# psc3m6 register map
Vendor: Infineon Technologies; Series: PSC3M6; File version: 1.0
CPU: CM33 r0p1, little endian, MPU, FPU, DSP, VTOR, 3 interrupt priority bits, 167 interrupts
Registers are 32-bit, read-write, reset 0x0 unless marked. A register's access mark holds for its fields unless they carry their own. Offsets are from the block's base; [hi:lo] are bit positions; lines under a group give offsets from that group; {n}, {i} and the like mark numbered series; <NAME> marks a mode.

## FLASHC
Base 0x42150000
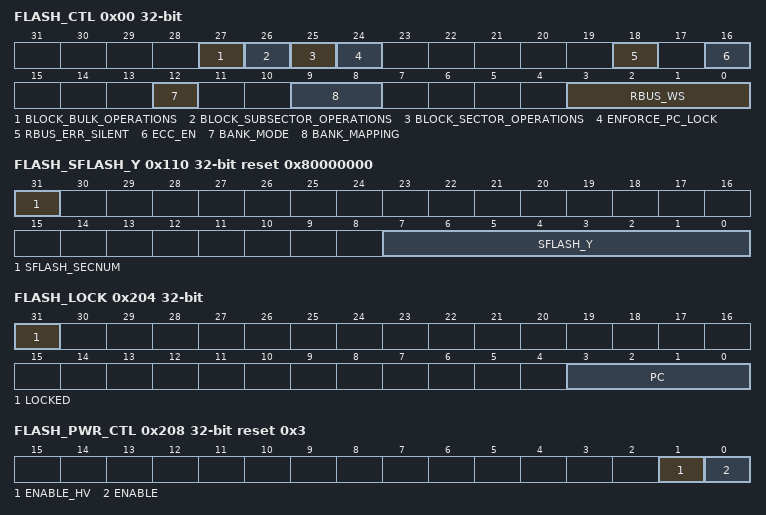
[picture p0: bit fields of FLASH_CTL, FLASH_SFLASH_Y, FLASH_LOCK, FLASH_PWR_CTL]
0x00 FLASH_CTL — Flash control
  [27] BLOCK_BULK_OPERATIONS write-1-sets — This bit can be set once and not cleared thereafter. When set it is no longer possible to perform bulk erase or bulk DFT operations. The flash controller will block any write operations to the FM_CTL register pertaining to such operations.
  [26] BLOCK_SUBSECTOR_OPERATIONS write-1-sets — This bit can be set once and not cleared thereafter. When set it is no longer possible to perform subsector erase or subsector DFT operations. The flash controller will block any write operations to the FM_CTL register pertaining to such operations.
  [25] BLOCK_SECTOR_OPERATIONS write-1-sets — This bit can be set once and not cleared thereafter. When set it is no longer possible to perform sector erase or sector DFT operations. The flash controller will block any write operations to the FM_CTL register pertaining to such operations.
  [24] ENFORCE_PC_LOCK write-1-sets — This bit can be set once and not cleared thereafter. When set the PC inheritiance and locking mechanism described with the FLASH_LOCK register is enabled. When cleared, access to the flash controller and flash macro is possible from any protection context with appropriate PPC permissions.
  [18] RBUS_ERR_SILENT — Please note that it is SW's responsibility that I$ of M33 must be disabled before setting RBUS_ERR_SILENT HIGH. Otherwise, the erroneous goes to I$ which is NOT desired. Specifies bus transfer behavior for a non-recoverable error on the FLASH macro main interface (either a non-correctable ECC error, a FLASH macro main interface internal error, a FLASH macro main interface memory hole access): 0: Bus transfer has a bus error. 1: Bus transfer does NOT have a bus error; i.e. the error is 'silent' In either case, the erroneous FLASH macro data is returned to CPU since I$ is disabled. This field is ONLY used by CPU bus transfers. Non-CPU bus transfers always have a bus transfer with a bus error and fault/interrupt, in case of a non-recoverable error. Note: All CPU bus masters have dedicated status registers (CM33 to register the occurrence of FLASH macro main interface (R-bus) internal errors. Note: fault reporting can be used to identify the error that occurred: - FLASH macro main interface internal error. - FLASH macro main interface non-recoverable ECC error. - FLASH macro main interface recoverable ECC error (over its threshold). - FLASH macro main interface memory hole error.
  [16] ECC_EN — Enable ECC checking for FLASH main (R-bus) interface: 0: Disabled. ECC checking/reporting on FLASH main interface is disabled. No correctable or non-correctable faults are reported. 1: Enabled.
  [12] BANK_MODE — Specifies bank mode of FLASH macro main array. 0: Single bank mode. 1: Dual bank mode.
  [9:8] BANK_MAPPING — Specifies mapping of FLASH macro main subregion. 00: MAIN (Mapping A), WORK (Mapping A). 01: MAIN (Mapping B), WORK (Mapping A). 10: MAIN (Mapping A), WORK (Mapping B). 11: MAIN (Mapping B), WORK (Mapping B). This field is only used when MAIN_BANK_MODE is '1' (dual bank mode).
  [3:0] RBUS_WS — FLASH macro main interface (R-bus) wait states: '0': 0 wait states. ... '15': 15 wait states
0x104 FLASH_SECTOR_M ro — # of sector of a FM
  [31:0] SECTOR_M — # of sectors of a FM, must be an even number, same value as RTL parameter SECTOR_M.
0x108 FLASH_MAIN_N ro — Size of MAIN in 8KB block for each pair of sectors
  [31:0] MAIN_N — Size of MAIN_NVM in 8KB blocks for each pair of sectors, same value as RTL parameter MAIN_N.
0x10C FLASH_WORK_Z ro — Size of WORK in 8KB block for each pair of sectors
  [31:0] WORK_Z — Size of WORK_NVM in 8KB blocks for each pair of sectors, same value as RTL parameter WORK_Z, the value WORK_Z can be zero.
0x110 FLASH_SFLASH_Y ro reset 0x80000000 — Size of SLFASH in 8KB block in Sector 1
  [31] SFLASH_SECNUM — 0: Not allowed 1: SM only in Sector 1
  [7:0] SFLASH_Y — Size of SFLASH_NVM in 8KB blocks in Sector 1, same value as RTL parameter SFLASH_Y.
0x114 FLASH_REFRESH_ROW ro — Size of refresh rows for each sector
  [31:0] REFRESH_ROW — Size of refresh rows for each sector, same value as RTL parameter REFRESH_ROW All sectors of a FM must have the same refresh rows It is 4 per sector for s40flash.3 FM.
0x200 FLASH_CMD — Command
  [1] BUFF_INV write-1-sets — Invalidation of ALL buffers. SW writes a '1' to clear the buffers. HW sets this field to '0' when the operation is completed. The operation takes a maximum of three clock cycles.
0x204 FLASH_LOCK — Flash Controller Lock Register
  [31] LOCKED — Software writes this register bit to 1 to 'lock' the flash controller to its own protection context (after setting the protection context by writing to a flash memory location). Once set, any subsequent (AHB) writes result in bus error and operation ignored. Software (FLASH.PC) reads back this field to check whether the lock succeeded. Software (FLASH_LOCK.PC) clears this field when it has completed a program/erase operation. To avoid deadlock and for management purpose, HW entitles PC0 the omnipotent capability to read FLASH_LOCK.PC and to release FLASH_LOCK.LOCKED no matter which PC acquires it. All PCs allowed by PPC can access FLASH_LOCK when its LOCKED bit is LOW (not locked).
  [3:0] PC ro — When FLASH_LOCK is acquired, even PPC allows, further MMIO access is possible only to this FLASH_LOCK.PC (& same HMASTER_ID) irrespective of corresponding PPC attributes. Other PCs or the same PC but different HMASTER_ID violation results in bus error & operation ignored. There is no further interrupt/fault triggered for this violation.
0x208 FLASH_PWR_CTL reset 0x3 — Flash power control
  [1] ENABLE_HV — Controls 'enable_hv' pin of the Flash memory.
  [0] ENABLE — Controls 'enable' pin of the Flash memory.
0x20C ENFORCE_PC_LOCK_SHADOW ro — Shadow bit of FLASH_CTL.ENFORCE_PC_LOCK
  [0] PC_LOCK_SHADOW — Shadow register of FLASH_CTL.ENFORCE_PC_LOCK. Read only irrespective of PPC's configuration.
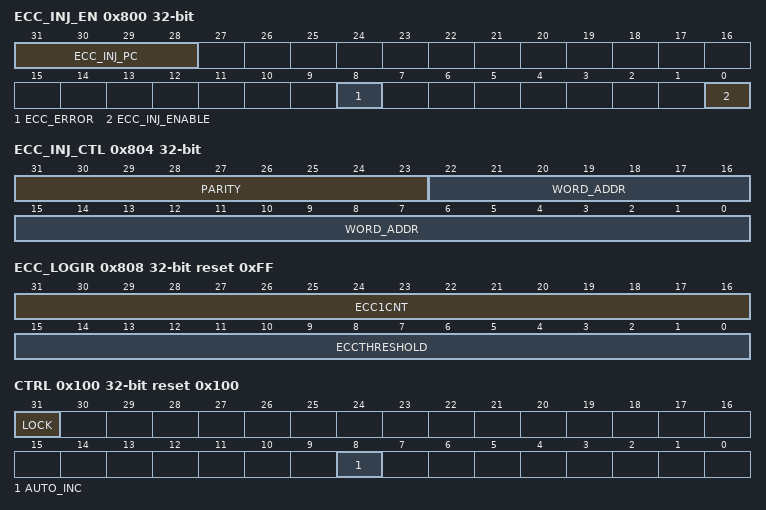
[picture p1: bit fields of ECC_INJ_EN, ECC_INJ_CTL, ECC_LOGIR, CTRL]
0x800 ECC_INJ_EN — ECC injection enable on read
  [31:28] ECC_INJ_PC ro — The PC is inherited from the master who enabled ECC_INJ_ENABLE (while ECC_INJ_ENABLE is low)
  [8] ECC_ERROR — 1'b0: If the injected ECC does not trigger any non-recoverable error (ECC errors <= 1). 1'b1: If the injected ECC triggers non-recoverable error (ECC errors >= 2). The AHB read transaction results in bus error. There is no additional fault/interrupt trigged. SW writes to this register are ignored if SW writes value other than the real RTL value (there is HW write when value written from SW does not match with the RTL value for this). The mxs40flashc HW clears ECC_INJ_EN.ECC_ERROR when SW clears ECC_INJ_EN.ECC_ERROR or ECC_INJ_EN.ECC_INJ_ENABLE (write value of '0').
  [0] ECC_INJ_ENABLE — Enable ECC error injection for FLASH R-bus interface (while FLASH_CTL.ECC_EN enabled) . 1'b0: ECC_INJ_EN is disabled. 1'b1: ECC_INJ_EN is enabled. Only the PC specified by ECC_INJ_PC can access (read/write) ECC_INJ_ENABLE and ECC_ERROR when ECC_INJ_ENABLE is high excpet PC0 which can access it at any time to break the potential deadlock of ECC_INJ_EN.
0x804 ECC_INJ_CTL — ECC injection control
  [31:23] PARITY — ECC parity to use for ECC error injection at address WORD_ADDR. The 9-bit ECC PARITY[8:0] is for a 128bit long word.
  [22:0] WORD_ADDR — Specifies the word address where an error will be injected. The word address WORD_ADDR[22:0] is FM column address (module-internal offset), including cxa, bax, axa, sector, row/page definitions. On a FLASH R-bus read and when ECC_INJ_EN bit is '1', and when ECC_INJ_EN.ECC_INJ_PC value matches, the parity (PARITY[8:0]) replaces the FM parity. When ECC_INJ_ENABLE is 1'b1, only PC specified by ECC_INJ_EN.ECC_INJ_PC can access (read/write) WORD_ADDR and PARITY.
0x808 ECC_LOGIR reset 0xFF — Interrupt threshold for number of ECC correctable error
  [31:16] ECC1CNT — Number of ECC single-bit failures detected and corrected during the memory read operations. Write value of 16'b0 is allowed to clear ECC_LOGIR.ECC1CNT (when the number of ECC single-bit failures detected and corrected reaches threshold value). It is recommended that SW should not write any value other than 0 to register ECC_LOGIR.ECC1CNT
  [15:0] ECCTHRESHOLD — Interrupt/fault threshold for number of ECC single-bit failures detected and corrected indicated in bit[31:16]. The # of failures must be one larger than ECCTHRESHOLD to trigger interrupt/fault.' For example, while ECCTHRESHOLD is 0xFF, only upon the 256th failures, the ECC Fault information will be reported on flashc_main_c_ecc_mmio_fault_* output pins (fault will be triggered). After the 256th failures, ECC_LOGIR.ECC1CNT will stay saturated at 0xFF and will not overrun. ECCTHRESHOLD of zero is not supported.
0x1000 MPC group — MPC Memory Protection Controller registers
  0x00 CFG — Config register with error response, RegionID PPC_MPC_MAIN is the security owner PC. The error response configuration is located in CFG.RESPONSE, only one such configuration exists applying to all protection contexts in the system.
    [4] RESPONSE — Response Configuration for Security and PC violations 0: Read-Zero Write Ignore (RAZ/WI) 1: Bus Error
  0x100 CTRL reset 0x100 — Control register with lock bit and auto-increment only (Separate CTRL for each PC depends on access_pc)
    [31] LOCK write-1-sets — Security lockdown for this protection context. Software can set this bit but not clear it once set. When set, write operations to BLK_LUT are not possible from this protection context. Setting LOCK also blocks writes to CTRL itself (for that PC copy). All writes are ignored.
    [8] AUTO_INC — Auto-increment BLK_IDX by 1 for this protection context as a side effect of each read/write access to BLK_LUT
  0x104 BLK_MAX ro — Max value of block-based index register
    [31:0] VALUE — Maximum value of block-based index register. The number and size blocks in an MPC is design time configurable and for embedded memories defaults to covering the entire memory using 4kB blocks; See product datasheet for details on protection of external memories.
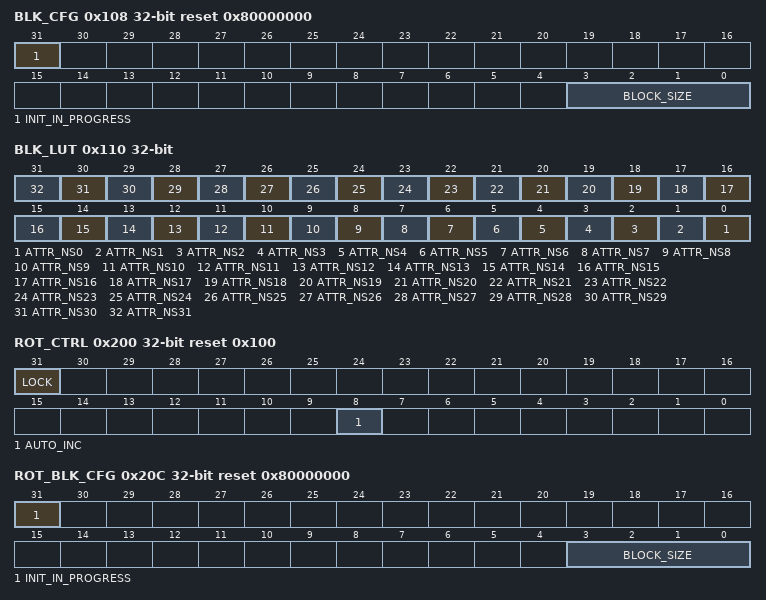
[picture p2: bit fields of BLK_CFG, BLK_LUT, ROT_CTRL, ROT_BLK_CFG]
  0x108 BLK_CFG ro reset 0x80000000 — Block size & initialization in progress
    [31] INIT_IN_PROGRESS — During initialization INIT_IN_PROGRESS is '1' and MMIO register accesses to BLK_LUT is blocked (BLK_IDX increment is also ignored). The block attributes are retained in DeepSleep (and obviously Active) power mode. Initialization is only required from a power mode in which the block attributes are not retained. E.g., initialization is required for a cold boot (after a Power-on-Reset). HW initializes the block attributes: the NS attributes are set to '0' (secure), the R attributes are set to '1' (read access allowed) and the W attributes are set to '1' (write access allowed). During initialization, the MPC supports memory accesses (memory accesses are NOT blocked) with the initialization block attribute values as mentioned above. This e.g. allows MPC initialization to proceed in parallel with boot program memory accesses (as opposed to serializing the two), improving device boot time.
    [3:0] BLOCK_SIZE — Block size of individually protected blocks (0: 32B, 1: 64B, ... up to 15: 1MB) Block size= (1<<(BLOCK_SIZE+5)) The number and size blocks in an MPC is design time configurable and for embedded memories defaults to covering the entire memory using 4kB blocks; see product datasheet for details on protection of external memories.
  0x10C BLK_IDX — Index of 32-block group accessed through BLK_LUT (Separate IDX for each PC depending on access_pc)
    [31:0] VALUE — Index value for accessing block-based lookup table using BLK_LUT. Programming out of LUT range is an user error and it loops back to '0' once overflow occurs.
  0x110 BLK_LUT — NS status for 32 blocks at BLK_IDX with PC=<access_pc>
    [n] ATTR_NS{n} (n=0..31) — NS bit for block {n} based on BLK_IDX
  0x200 ROT_CTRL reset 0x100 — Control register with lock bit and auto-increment only
    [31] LOCK write-1-sets — Security lockdown for the root-of-trust configuration registers. Software can set this bit but not clear it once set. When set, write operations to ROT_BLK_LUT are not possible. Write is ignored.
    [8] AUTO_INC — Auto-increment ROT_BLK_IDX by 1 for each read/write of ROT_BLK_LUT
  0x208 ROT_BLK_MAX ro — Max value of block-based index register for ROT
    [31:0] VALUE — Maximum value of block-based index register. The number and size blocks in an MPC is design time configurable and for embedded memories defaults to covering the entire memory using 4kB blocks; see product datasheet for details on protection of external memories.
  0x20C ROT_BLK_CFG ro reset 0x80000000 — Same as BLK_CFG
    [31] INIT_IN_PROGRESS — During initialization INIT_IN_PROGRESS is '1' and MMIO register accesses to ROT_BLK_LUT is RAZWI. The block attributes are retained in DeepSleep (and obviously Active) power mode. Initialization is only required from a power mode in which the block attributes are not retained. E.g., initialization is required for a cold boot (after a Power-on-Reset). HW initializes the block attributes: the NS attributes are set to '0' (secure), the R attributes are set to '1' (read access allowed) and the W attributes are set to '1' (write access allowed). During initialization, the MPC supports memory accesses (memory accesses are NOT blocked) with the initialization block attribute values as mentioned above. This e.g. allows MPC initialization to proceed in parallel with boot program memory accesses (as opposed to serializing the two), improving device boot time.
    [3:0] BLOCK_SIZE — Block size of individually protected blocks (0: 32B, 1: 64B, ...up to 15:1MB) Block size= (1<<(BLOCK_SIZE+5)) The number and size blocks in an MPC is design time configurable and for embedded memories defaults to covering the entire memory using 4kB blocks; see product datasheet for details on protection of external memories.
  0x210 ROT_BLK_IDX — Index of 8-block group accessed through ROT_BLK_LUT_*
    [31:0] VALUE — Index value for accessing block-based lookup table using ROT_BLK_LUT. Programming out of LUT range is an user error and it loops back to '0' once overflow occurs.
  0x214 ROT_BLK_PC — Protection context of 8-block group accesses through ROT_BLK_LUT
    [3:0] PC — Specify PC values for ROT_BLK_IDX and ROT_BLK_LUT
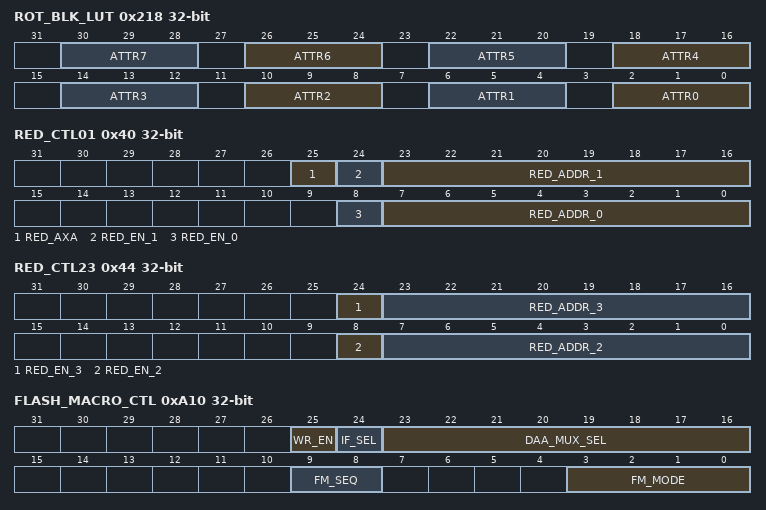
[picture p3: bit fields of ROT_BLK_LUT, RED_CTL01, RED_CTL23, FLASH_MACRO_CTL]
  0x218 ROT_BLK_LUT — (R,W,NS) bits for 8 blocks at ROT_BLK_IDX for PC=ROT_BKL_PC
    [4n+2:4n] ATTR{n} (n=0..7) — W/R/NS bits for block {n} indicated by ROT_BLK_IDX for ROT_BLK_PC PC
0x2000 FM_CTL group — Flash Macro Registers are maintained by SONOS FM team. Please read 002-26677 BROS for details.
  0x40 RED_CTL01 — Redundancy Control normal sectors 0,1
    [25] RED_AXA — '1': Redundancy Enable for SM Rows in Sector 1; Uses RED_ADDR_1 bits for Bad Row Pair Address
    [24] RED_EN_1 — '1': Redundancy Enable for Sector 1
    [23:16] RED_ADDR_1 — Bad Row Pair Address for Sector 1
    [8] RED_EN_0 — '1': Redundancy Enable for Sector 0
    [7:0] RED_ADDR_0 — Bad Row Pair Address for Sector 0
  0x44 RED_CTL23 — Redundancy Control normal sectors 2,3
    [24] RED_EN_3 — 1': Redundancy Enable for Sector 3
    [23:16] RED_ADDR_3 — Bad Row Pair Address for Sector 3
    [8] RED_EN_2 — 1': Redundancy Enable for Sector 2
    [7:0] RED_ADDR_2 — Bad Row Pair Address for Sector 2
  {0x800+4j} FM_PL_DATA[{j}] (j=0..131) — Flash macro Page Latches data
    [31:0] DATA32 — Normal PL data read: four page latch Bytes When reading the page latches it requires FM_CTL.IF_SEL to be '1' Note: the high Voltage page latches are readable for test mode functionality.
  0xA10 FLASH_MACRO_CTL — Flash macro control
    [25] WR_EN — 0: normal mode 1: Fm Write Enable Note: IF_SEL and WR_EN cannot be changed at the same time
    [24] IF_SEL — Interface selection. Specifies the interface that is used for flash memory read operations: 0: R interface is used (default value). In this case, the flash memory address is provided as part of the R signal interface. 1: C interface is used. In this case, the flash memory address is provided by FM_MEM_ADDR (the page address) and by the C interface access offset in the FM_MEM_DATA structure. Note: IF_SEL and WR_EN cannot be changed at the same time
    [23:16] DAA_MUX_SEL — Direct memory cell access address.
    [9:8] FM_SEQ — Requires (IF_SEL|WR_EN)=1 Flash macro sequence selection
    [3:0] FM_MODE — Requires (IF_SEL|WR_EN)=1 Flash macro mode selection
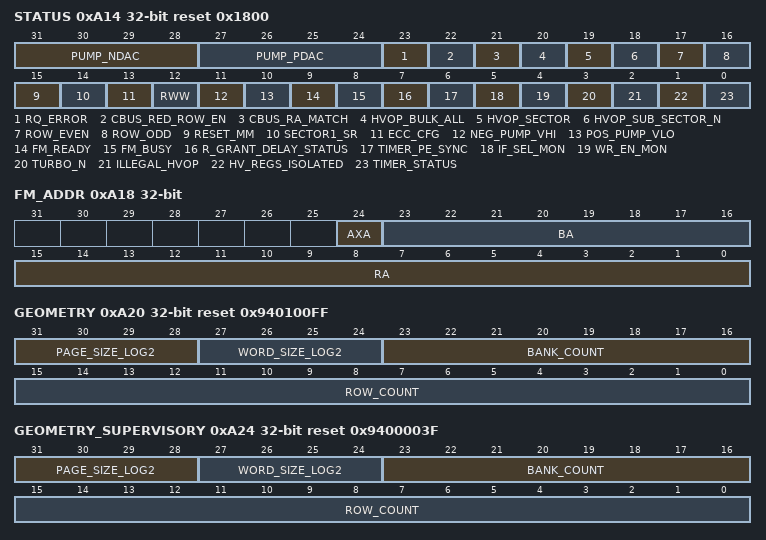
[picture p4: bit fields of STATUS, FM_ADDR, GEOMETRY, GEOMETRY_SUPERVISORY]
  0xA14 STATUS ro reset 0x1800
    [31:28] PUMP_NDAC — Test_only, internal node: regif ndac outputs to pos pump
    [27:24] PUMP_PDAC — Test_only, internal node: regif pdac outputs to pos pump
    [23] RQ_ERROR — Test_only, internal node: rq_error sync-de in clk_c domain
    [22] CBUS_RED_ROW_EN — Test_only, internal node: mpcon red_row_en
    [21] CBUS_RA_MATCH — Test_only, internal node: mpcon ra match
    [20] HVOP_BULK_ALL — Test_only, internal node: mpcon bk_all
    [19] HVOP_SECTOR — Test_only, internal node: mpcon bk_sec
    [18] HVOP_SUB_SECTOR_N — Test_only, internal node: mpcon bk_subb
    [17] ROW_EVEN — Test_only, internal node: mpcon row_even
    [16] ROW_ODD — Test_only, internal node: mpcon row_odd
    [15] RESET_MM — Test_only, internal node: mpcon reset_mm
    [14] SECTOR1_SR — 0: Sector 1 does not contain special rows. The special rows are located in separate special sectors. 1: Sector 1 contains special rows
    [13] ECC_CFG — Geometry ECC configuration: 0: FM with No ECC 1: FM with ECC
    [12] RWW — FM Type (Read While Write or Not Read While Write): 0: Non RWW FM Type 1: RWW FM Type
    [11] NEG_PUMP_VHI
    [10] POS_PUMP_VLO
    [9] FM_READY — 0: FM not ready 1: FM ready
    [8] FM_BUSY — 0': FM not busy 1: FM BUSY : R_GRANT is 0 as result of a busy request from FM ready, or from HV operations.
    [7] R_GRANT_DELAY_STATUS — 0: R_GRANT_DELAY timer is not running 1: R_GRANT_DELAY timer is running
    [6] TIMER_PE_SYNC — The actual timer state sync-ed in clk_c domain: 0: timer is not running: 1: timer is running;
    [5] IF_SEL_MON — FM_CTL.IF_SEL bit after being synchronized in clk_r domain
    [4] WR_EN_MON — FM_CTL.WR_EN bit after being synchronized in clk_r domain
    [3] TURBO_N — After FM power up indicates the analog blocks currents are boosted to faster reach their functional state.. Used in the testchip boot only as an 'FM READY' flag. 0: turbo mode 1: normal mode
    [2] ILLEGAL_HVOP — Indicates a bulk,sector erase, program has been requested when axa=1 0: no error 1: illegal HV operation error
    [1] HV_REGS_ISOLATED — Indicates the isolation status at HV trim and redundancy registers inputs 0: Not isolated, writing permitted 1: isolated writing disabled
    [0] TIMER_STATUS — This is the timer_en bit set by writing a '1' in the TIMER_CTL bit 31. It is reset by HW when the timer expires 0: timer not running 1: Timer is enabled and not expired yet
  0xA18 FM_ADDR — Flash macro address
    [24] AXA — Auxiliairy address field: 0: regular flash memory. 1: supervisory flash memory.
    [23:16] BA — Bank address.
    [15:0] RA — Row address.
  0xA1C BOOKMARK — Bookmark register - keeps the current FW HV seq
    [31:0] BOOKMARK — Used by FW. Keeps the Current HV cycle sequence
  0xA20 GEOMETRY ro reset 0x940100FF — Regular flash geometry
    [31:28] PAGE_SIZE_LOG2 — Number of Bytes per page (log 2): 0: 1 Byte 1: 2 Bytes 2: 4 Bytes ... 15: 32768 Bytes The currently planned flash macros have a page size of either 256 Byte or 512 Byte, resulting in PAGE_SIZE_LOG2 settings of 8 and 9 respectively. All 4 macros used in the PSC3M6 family will see this field as 9
    [27:24] WORD_SIZE_LOG2 — Number of Bytes per word (log 2). A word is defined as the data that is read from the flash macro over the R interface with a single read access: 0: 1 Byte 1: 2 Bytes 2: 4 Bytes ... 3: 128 Bytes The currently planned flash macros have a word size of either 32-bit, 64-bit or 128-bit, resulting in WORD_SIZE_LOG2 settings of 2, 3 and 4 respectively. All 4 macros used in the PSC3M6 family will see this field as 4
    [23:16] BANK_COUNT — Number of banks (minus 1): 0: 1 bank 1: 2 banks ... '255': 256 banks For 128kB, 256kB and 512kB macros the value of this field is 1 (2 banks) For 1MB macro the value of this field is 3 (4 banks)
    [15:0] ROW_COUNT — Number of rows (minus 1): 0: 1 row 1: 2 rows 2: 3 rows ... '65535': 65536 rows For 128kB macro the value of this field is x7F (128 rows) For 256kB macro the value of this field is xFF (256 rows) For 512kB macro the value of this field is x1FF (512 rows) For 1MB macro the value of this field is x1FF (512 rows)
  0xA24 GEOMETRY_SUPERVISORY ro reset 0x9400003F — Supervisory flash geometry
    [31:28] PAGE_SIZE_LOG2 — Number of Bytes per page (log 2). See GEOMETRY.PAGE_SIZE_LOG2. Typically, PAGE_SIZE_LOG2 equals GEOMETRY.PAGE_SIZE_LOG2.
    [27:24] WORD_SIZE_LOG2 — Number of Bytes per word (log 2). See GEOMETRY.WORD_SIZE_LOG2. Typically, WORD_SIZE_LOG2 equals GEOMETRY.WORD_SIZE_LOG2.
    [23:16] BANK_COUNT — Number of banks (minus 1). BANK_COUNT is less or equal to GEOMETRY.BANK_COUNT.
    [15:0] ROW_COUNT — Number of rows (minus 1). ROW_COUNT is typically less than GEOMETRY.ROW_COUNT
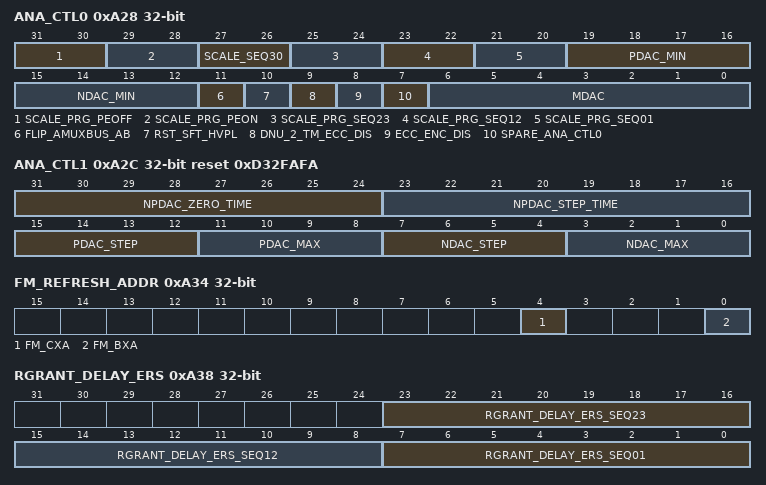
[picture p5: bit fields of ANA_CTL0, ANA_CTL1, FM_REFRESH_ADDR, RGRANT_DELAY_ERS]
  0xA28 ANA_CTL0 — Analog control 0
    [31:30] SCALE_PRG_PEOFF — PROG&PRE_PROG: Scale for R_GRANT_DELAY on PE OFF transition: 00: 0.125uS 01: 1uS 10: 10uS 11: 100uS
    [29:28] SCALE_PRG_PEON — PROG&PRE_PROG: Scale for R_GRANT_DELAY on PE On transition: 00: 0.125uS 01: 1uS 10: 10uS 11: 100uS
    [27:26] SCALE_SEQ30 — PROG&PRE_PROG& ERASE: Scale for R_GRANT_DELAY on seq3-seq0 transition: 00: 0.125uS 01: 1uS 10: 10uS 11: 100uS
    [25:24] SCALE_PRG_SEQ23 — PROG&PRE_PROG: Scale for R_GRANT_DELAY on seq2-seq3 transition: 00: 0.125uS 01: 1uS 10: 10uS 11: 100uS
    [23:22] SCALE_PRG_SEQ12 — PROG&PRE_PROG: Scale for R_GRANT_DELAY on seq1-seq2 transition: 00: 0.125uS 01: 1uS 10: 10uS 11: 100uS
    [21:20] SCALE_PRG_SEQ01 — PROG&PRE_PROG: Scale for R_GRANT_DELAY on seq0-seq1 transition: 00: 0.125uS 01: 1uS 10: 10uS 11: 100uS
    [19:16] PDAC_MIN — PDAC staircase min value
    [15:12] NDAC_MIN — NDAC staircase min value
    [11] FLIP_AMUXBUS_AB — Flips amuxbusa and amuxbusb 0: amuxbusa, amuxbusb 1: amuxbusb, amuxbusb
    [10] RST_SFT_HVPL — 1: Page Latches Soft Reset
    [9] DNU_2_TM_ECC_DIS ro — Do Not Use this bit as it is for test Mode use only. Write only to 0 in normal mode (tm_ecc_dis in RTL)
    [8] ECC_ENC_DIS — 0': ECC encoder is enabled for the FM with ECC feature. The PL ECC bits are loaded automatically '1': ECC encoder disabled. - The Macro needs to be in C-BUS mode - IF_SEL=1 to write and keep this bit at 1
    [7] SPARE_ANA_CTL0 — Spare bit
    [6:0] MDAC — Trimming of the output margin Voltage as a function of Vpos and Vneg.
  0xA2C ANA_CTL1 reset 0xD32FAFA — Analog control 1
    [31:24] NPDAC_ZERO_TIME — Ndac/Pdac LO duration: (1uS .. 255uS) * 8 When 0, N/PDAC don't return to 0
    [23:16] NPDAC_STEP_TIME — Ndac/Pdac step duration: (1uS .. 255uS) * 8 When = 0 N/PDAC_MAX control the pumps
    [15:12] PDAC_STEP — Pdac step increment
    [11:8] PDAC_MAX — Pdac Max Value.Trimming of positive pump output Voltage:
    [7:4] NDAC_STEP — Ndac step increment
    [3:0] NDAC_MAX — Ndac Max Value.Trimming of negative pump output Voltage.
  0xA30 FM_PL_WRDATA_ALL — Flash macro write page latches all
    [31:0] DATA32 — Write all high Voltage page latches with the same 32-bit data in a single write cycle. In order to also write same lower 8bit from 32-bit data to all the ECC bits in the page latches, set ANA_CTL0.ECC_ENC_DIS=1. Read always returns 0. Used for test mode and sims only
  0xA34 FM_REFRESH_ADDR — Address bit to point to scratch area
    [4] FM_CXA — Address bit to point to Column 33 0: Point to normal columns in sector 1: Point to Column 33 used for BL Disturb Counter. For engineering use only.
    [0] FM_BXA — Address bit to point to scratch area 0: Point to normal rows in sector 1: Point to scratch rows in sector. For engineering use only.
  0xA38 RGRANT_DELAY_ERS — R-grant delay for erase
    [23:16] RGRANT_DELAY_ERS_SEQ23 — ERASE: R-grant blocking delay on seq2-seq3 transition. Scale = ANA_CTL0.SCALE_SEQ23 When = 0 R_GRANT_DELAY control is disabled when IF_SEL=1 R_GRANT_DELAY control is disabled
    [15:8] RGRANT_DELAY_ERS_SEQ12 — ERASE: R-grant blocking delay on seq1-seq2 transition. Scale = ANA_CTL0.SCALE_SEQ12 When = 0 R_GRANT_DELAY control is disabled when IF_SEL=1 R_GRANT_DELAY control is disabled
    [7:0] RGRANT_DELAY_ERS_SEQ01 — ERASE: R-grant blocking delay on seq0-seq1 transition. Scale = ANA_CTL0.SCALE_SEQ01 When = 0 R_GRANT_DELAY control is disabled when IF_SEL=1 R_GRANT_DELAY control is disabled
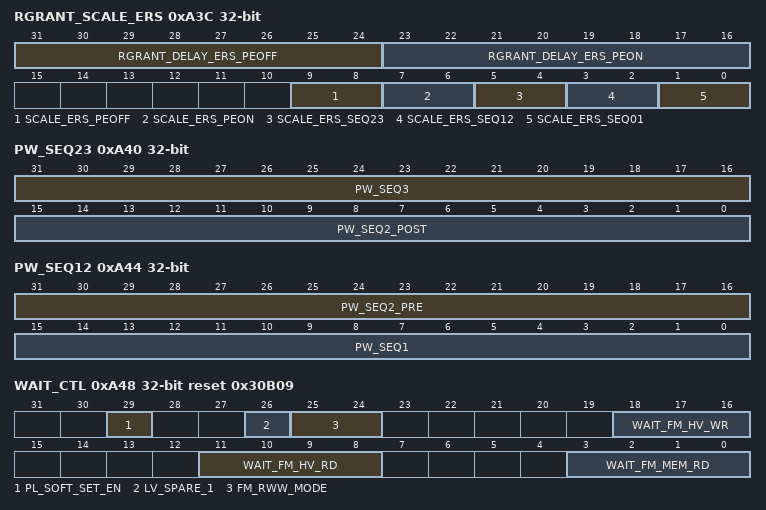
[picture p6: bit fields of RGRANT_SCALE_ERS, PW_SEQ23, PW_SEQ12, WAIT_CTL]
  0xA3C RGRANT_SCALE_ERS — R-grant delay scale for erase
    [31:24] RGRANT_DELAY_ERS_PEOFF — ERASE: R-grant blocking delay on PE OFF. Scale = ANA_CTL0.SCALE_PEOFF When = 0 R_GRANT_DELAY control is disabled when IF_SEL=1 R_GRANT_DELAY control is disabled
    [23:16] RGRANT_DELAY_ERS_PEON — ERASE: R-grant blocking delay on PE ON. Scale = ANA_CTL0.SCALE_PEON When = 0 R_GRANT_DELAY control is disabled when IF_SEL=1 R_GRANT_DELAY control is disabled
    [9:8] SCALE_ERS_PEOFF — ERASE: Scale for R_GRANT_DELAY on PE OFF transition: '00': 0.125uS '01': 1uS '10': 10uS '11': 100uS
    [7:6] SCALE_ERS_PEON — ERASE: Scale for R_GRANT_DELAY on PE On transition: '00': 0.125uS '01': 1uS '10': 10uS '11': 100uS
    [5:4] SCALE_ERS_SEQ23 — ERASE: Scale for R_GRANT_DELAY on seq2-seq3 transition: '00': 0.125uS '01': 1uS '10': 10uS '11': 100uS
    [3:2] SCALE_ERS_SEQ12 — ERASE: Scale for R_GRANT_DELAY on seq1-seq2 transition: '00': 0.125uS '01': 1uS '10': 10uS '11': 100uS
    [1:0] SCALE_ERS_SEQ01 — ERASE: Scale for R_GRANT_DELAY on seq0-seq1 transition: '00': 0.125uS '01': 1uS '10': 10uS '11': 100uS
  0xA40 PW_SEQ23 — HV Pulse Delay for seq2 post & seq3
    [31:16] PW_SEQ3 — Seq3 delay
    [15:0] PW_SEQ2_POST — Seq2 post delay
  0xA44 PW_SEQ12 — HV Pulse Delay for seq 1&2 pre
    [31:16] PW_SEQ2_PRE — Seq2 pre delay
    [15:0] PW_SEQ1 — Seq1 delay
  0xA48 WAIT_CTL reset 0x30B09 — Wait State control
    [29] PL_SOFT_SET_EN — Page latch soft set enable, 0 = disabled, 1 = enabled (at end of seq_2), taken care in API
    [26] LV_SPARE_1 — Spare register
    [25:24] FM_RWW_MODE — 2'b00: Full CBUS MODE 2'b01: RWW 2'b10: RWW. R_GRANT is stalling r_bus for the whole program/erase duration
    [18:16] WAIT_FM_HV_WR — Number of C interface wait cycles (on 'clk_c') for a write to the Page Latches.
    [11:8] WAIT_FM_HV_RD — Number of C interface wait cycles (on 'clk_c') for a read from the Page Latches. Common for reading HV Page Latches and the DATA_COMP_RESULT bit
    [3:0] WAIT_FM_MEM_RD — Number of C interface wait cycles (on 'clk_c') for a read from the memory
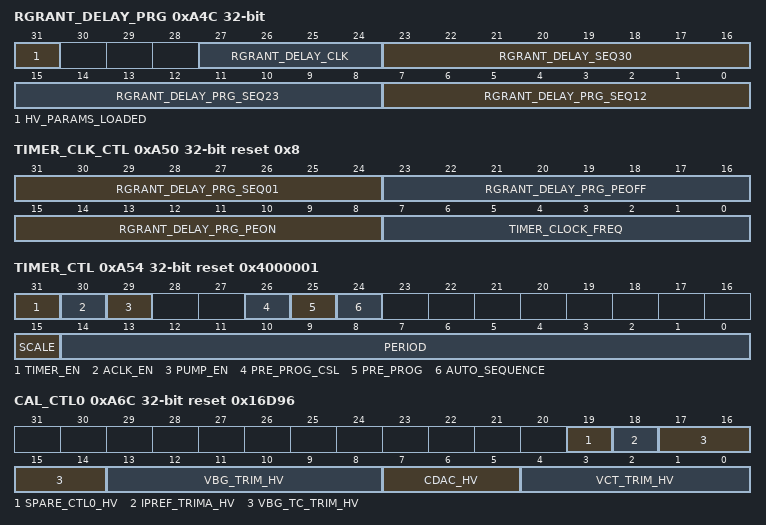
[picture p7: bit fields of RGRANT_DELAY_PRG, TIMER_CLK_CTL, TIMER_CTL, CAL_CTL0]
  0xA4C RGRANT_DELAY_PRG — R-grant delay for program
    [31] HV_PARAMS_LOADED — 0': HV Pulse common params not loaded '1': HV Pulse common params loaded: r-grant delays, r-grant scale, prescaler, timer values for seq1,seq2_pre, seq2_post, seq3
    [27:24] RGRANT_DELAY_CLK — Frequency divider from clk_t to create the 8MHz reference clock for R_grant delay. The value of 0 is equivalent with 1. If the clock clk_t = 8MHz the value needs to be 1 The value of this field is the integer result of 'clk_t frequency / 8'. Example: for clk_t=100 this field is INT(100/8) =12. This field is updated at runtime with the 'SW_RGRANT_DELAY_CLK ' value from the HV parameters table
    [23:16] RGRANT_DELAY_SEQ30 — PROG&PRE_PROG & ERASE: R-grant blocking delay on seq3-seq0 transition. Scale = ANA_CTL0.SCALE_SEQ30 When = 0 R_GRANT_DELAY control is disabled when IF_SEL=1 R_GRANT_DELAY control is disabled
    [15:8] RGRANT_DELAY_PRG_SEQ23 — PROG&PRE_PROG: R-grant blocking delay on seq2-seq3 transition. Scale = ANA_CTL0.SCALE_SEQ23 When = 0 R_GRANT_DELAY control is disabled when IF_SEL=1 R_GRANT_DELAY control is disabled
    [7:0] RGRANT_DELAY_PRG_SEQ12 — PROG&PRE_PROG: R-grant blocking delay on seq1-seq2 transition. Scale = ANA_CTL0.SCALE_SEQ12 When = 0 R_GRANT_DELAY control is disabled when IF_SEL=1 R_GRANT_DELAY control is disabled
  0xA50 TIMER_CLK_CTL reset 0x8 — Timer prescaler (clk_t to timer clock frequency divider)
    [31:24] RGRANT_DELAY_PRG_SEQ01 — PROG&PRE_PROG: R-grant blocking delay on seq0-seq1 transition. Scale = ANA_CTL0.SCALE_SEQ01 When = 0 R_GRANT_DELAY control is disabled when IF_SEL=1 R_GRANT_DELAY control is disabled
    [23:16] RGRANT_DELAY_PRG_PEOFF — PROG&PRE_PROG: R-grant blocking delay on PE OFF. Scale = ANA_CTL0.SCALE_PEOFF When = 0 R_GRANT_DELAY control is disabled when IF_SEL=1 R_GRANT_DELAY control is disabled
    [15:8] RGRANT_DELAY_PRG_PEON — PROG&PRE_PROG: R-grant blocking delay on PE ON. Scale = ANA_CTL0.SCALE_PEON When = 0 R_GRANT_DELAY control is disabled when IF_SEL=1 R_GRANT_DELAY control is disabled
    [7:0] TIMER_CLOCK_FREQ — Clk_t frequency divider to provide the 1MHz reference clock for the Regif Timer. Equal to the frequency in MHz of the timer clock 'clk_t'. Example: if 'clk_t' has a frequency of 4 MHz then this field value is '4' Max clk_t frequency = 100MHz. This field is updated at runtime with the 'SW_TIMER_CLOCK_FREQ ' value from the HV parameters table
  0xA54 TIMER_CTL reset 0x4000001 — Timer control
    [31] TIMER_EN — Timer enable: 0: disabled 1: enabled. SW sets this field to '1' to start the timer. HW sets this field to '0' when the timer is expired.
    [30] ACLK_EN — ACLK enable (generates a single cycle pulse for the FM): 0: disabled 1: enabled. SW set this field to '1' to generate a single cycle pulse. HW sets this field to '0' when the pulse is generated.
    [29] PUMP_EN — Pump enable: 0: disabled 1: enabled (also requires FM_CTL.IF_SEL to be'1', this additional restriction is required to prevent non intentional clearing of the FM). SW sets this field to '1' to generate a single PE pulse. HW clears this field when timer is expired.
    [26] PRE_PROG_CSL — 0: CSL lines driven by MDAC 1: CSL lines driven by VNEG_G
    [25] PRE_PROG — 1 during pre-program operation
    [24] AUTO_SEQUENCE — 1': Starts1 the HV automatic sequencing Cleared by HW
    [15] SCALE — Timer tick scale: 0: 1 microsecond. 1: 100 microseconds.
    [14:0] PERIOD — Timer period in either microseconds (SCALE is '0') or 100's of microseconds (SCALE is '1') multiples.
  0xA58 ACLK_CTL wo — MPCON clock
    [0] ACLK_GEN — Write '1b1' to generate one clock pulse for HV control registers (mpcon outputs)
  0xA5C INTR — Interrupt
    [0] TIMER_EXPIRED write-1-clears — Set to '1', when event is detected. Write INTR field with '1', to clear bit. Write INTR_SET field with '1', to set bit.
  0xA60 INTR_SET — Interrupt set
    [0] TIMER_EXPIRED write-1-sets — Write INTR_SET field with '1' to set corresponding INTR field (a write of '0' has no effect).
  0xA64 INTR_MASK — Interrupt mask
    [0] TIMER_EXPIRED — Mask for corresponding field in INTR register.
  0xA68 INTR_MASKED ro — Interrupt masked
    [0] TIMER_EXPIRED — Logical and of corresponding request and mask fields.
  0xA6C CAL_CTL0 reset 0x16D96 — Cal control - VCT, VBG, CDAC, IPREF
    [19] SPARE_CTL0_HV — Spare trim bits, DNU
    [18] IPREF_TRIMA_HV — Adds 100-150nA boost on IPREF
    [17:14] VBG_TC_TRIM_HV — Bandgap Voltage Temperature Compensation trim control
    [13:8] VBG_TRIM_HV — Bandgap Voltage trim control.
    [7:5] CDAC_HV — Temperature compensated trim DAC. To control Vctat slope for VNEG.
    [4:0] VCT_TRIM_HV — Bandgap Voltage Temperature Compensation trim control.
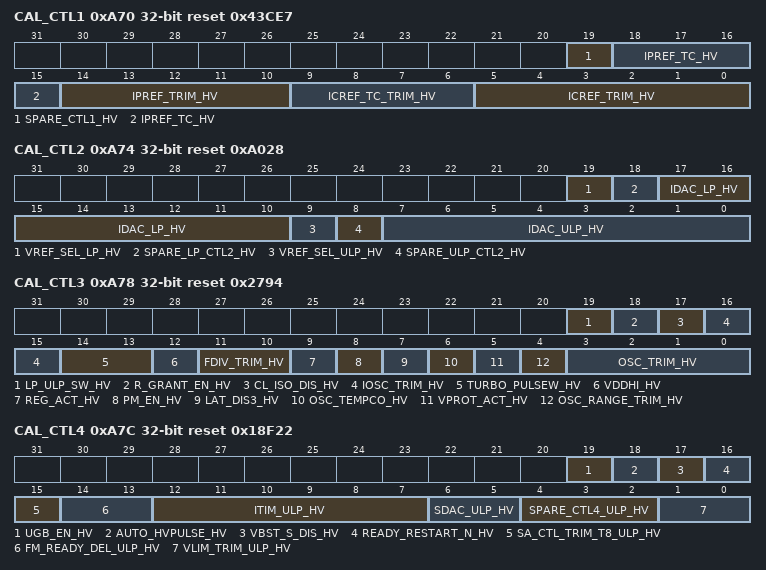
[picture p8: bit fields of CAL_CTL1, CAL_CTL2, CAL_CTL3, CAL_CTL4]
  0xA70 CAL_CTL1 reset 0x43CE7 — Cal control - ICREF, IPREF
    [19] SPARE_CTL1_HV — Spare trim bit, DNU
    [18:15] IPREF_TC_HV — IPREF Slope Control
    [14:10] IPREF_TRIM_HV — Bandgap IPTAT trim control.
    [9:6] ICREF_TC_TRIM_HV — Bandgap Current Temperature Compensation trim control
    [5:0] ICREF_TRIM_HV — Bandgap Current trim control.
  0xA74 CAL_CTL2 reset 0xA028 — Cal control - IDAC, IBS_CTL, LAT_DIS
    [19] VREF_SEL_LP_HV — 0: Uses VBG as reference for VLIM - LP Mode 1: Uses VCTAT as reference for VLIM - LP mode
    [18] SPARE_LP_CTL2_HV — Spare bit to be used in LP configuration
    [17:10] IDAC_LP_HV — Sets the sense current reference offset value. Refer to trim tables for details.
    [9] VREF_SEL_ULP_HV — 0: Uses VBG as reference for VLIM - ULP Mode 1: Uses VCTAT as reference for VLIM - ULP mode
    [8] SPARE_ULP_CTL2_HV — Spare bit to be used in ULP configuration
    [7:0] IDAC_ULP_HV — Sets the sense current reference offset value. Refer to trim tables for details.
  0xA78 CAL_CTL3 reset 0x2794 — Cal control - OSC trims, FDIV, REG_ACT, TURBO, LP_ULP_SW
    [19] LP_ULP_SW_HV — LP<-->ULP switch for trim signals: 0: LP 1: ULP
    [18] R_GRANT_EN_HV — 0: r_grant handshake disabled, r_grant always 1. 1: r_grant handshake enabled
    [17] CL_ISO_DIS_HV — 0: The internal logic controlls the CL isolation 1: Forces CL bypass
    [16:15] IOSC_TRIM_HV — Oscillator Bias Current Trim during Standby 0.33 uA -- 1.65 uA
    [14:13] TURBO_PULSEW_HV — Turbo pulse width trim (Typical) 00: 40 us 01: 20 us 10: 15 us 11: 8 us
    [12] VDDHI_HV — 0: vdd < 2.3V 1: vdd >= 2.3V '0' setting can used for vdd > 2.3V also, but with a current penalty.
    [11:10] FDIV_TRIM_HV — FDIV_TRIM_HV[1:0]: Assuming oscillator frequency of 8MHz in standby. Following are the clock frequencies seen by doubler 00: F = 0.5MHz 01: F = 1MHz 10: F = 2MHz 11: F = 4MHz
    [9] REG_ACT_HV — 0: VBST regulator will operate in active/standby mode based on control signal. 1: Forces the VBST regulator in active mode all the time
    [8] PM_EN_HV — 0: Sense Amp bias similar to _ver2 1: pbias enabled in Sense Amp for Better Margin
    [7] LAT_DIS3_HV — 0: Enable saen3 control for data out latches 1: Disable saen3 control for data out latches
    [6] OSC_TEMPCO_HV — 0: Uses VBG as reference 1: Uses VCTAT as reference
    [5] VPROT_ACT_HV — Forces VPROT in active mode all the time
    [4] OSC_RANGE_TRIM_HV — 0: Oscillator Low Frequency range 1: Oscillator High Frequency Range
    [3:0] OSC_TRIM_HV — Flash macro pump clock trim control.
  0xA7C CAL_CTL4 reset 0x18F22 — Cal control - VLIM, IDAC, SDAC, ITIM ULP trims
    [19] UGB_EN_HV — UGB enable in TM control
    [18] AUTO_HVPULSE_HV — 0: HV Pulse controlled by FW 1: HV Pulse controlled by Hardware
    [17] VBST_S_DIS_HV — 0: VBST_S voltage for each sector to allow VBST level to be dropped to VCC during Erase in the selected sector, reducing coupling to GBL. 1: VBST_S voltage for each sector stays at VBST level during Erase in the selected sector.
    [16] READY_RESTART_N_HV — Toggle: 1-->0, ready goes low, ready will remain low as long as the bit is low. Toggle the bit back to 1 to activate the ready logic. To be used by API only.
    [15] SA_CTL_TRIM_T8_ULP_HV — saen3 pulse width trim (Current trim)
    [14:13] FM_READY_DEL_ULP_HV — 00: Default : delay 1ns 01: Delayed by 1.5us 10: Delayed by 2.0us 11: Delayed by 2.5us
    [12:7] ITIM_ULP_HV — Trimming of timing current
    [6:5] SDAC_ULP_HV — Sets the sense current reference temp slope. Refer to trim tables for details.
    [4:2] SPARE_CTL4_ULP_HV
    [1:0] VLIM_TRIM_ULP_HV — VLIM_TRIM[1:0]: 00: V2 = 650mV 01: V2 = 700mV 10: V2 = 750mV - Default 11: V2 = 800mV
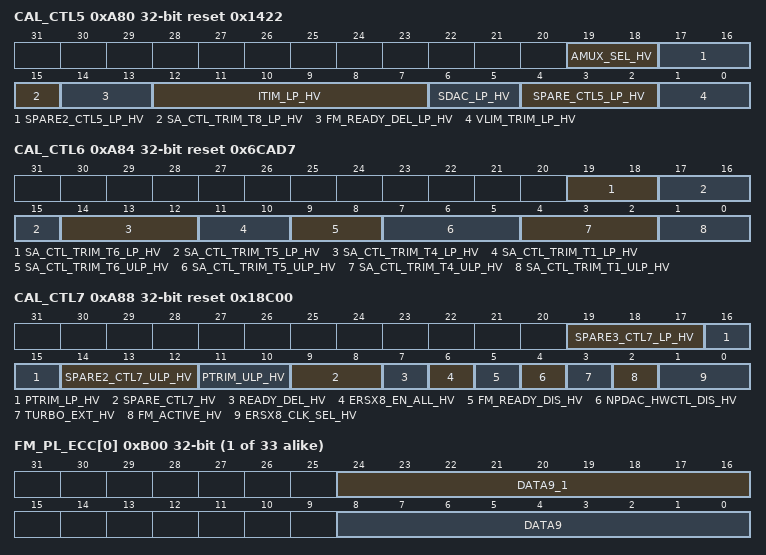
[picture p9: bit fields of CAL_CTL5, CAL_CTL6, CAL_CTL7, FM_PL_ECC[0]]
  0xA80 CAL_CTL5 reset 0x1422 — Cal control - VLIM, IDAC, SDAC, ITIM LP trims
    [19:18] AMUX_SEL_HV — Amux Select in AMUX_UGB 00: Bypass UGB for both amuxbusa and amuxbusb 01: Bypass UGB for amuxbusb while passing amuxbusa through UGB. 10: Bypass UGB for amuxbusa while passing amuxbusb through UGB. 11: UGB Calibrate mode
    [17:16] SPARE2_CTL5_LP_HV — Spare Bit, not used
    [15] SA_CTL_TRIM_T8_LP_HV — saen3 pulse width trim (Current trim)
    [14:13] FM_READY_DEL_LP_HV — 00: Delayed by 1us 01: Delayed by 1.5us 10: Delayed by 2.0us 11: Delayed by 2.5us
    [12:7] ITIM_LP_HV — Trimming of timing current
    [6:5] SDAC_LP_HV — Sets the sense current reference temp slope. Refer to trim tables for details.
    [4:2] SPARE_CTL5_LP_HV — Spare Bit, not used
    [1:0] VLIM_TRIM_LP_HV — VLIM_TRIM[1:0]: 00: V2 = 650mV 01: V2 = 700mV 10: V2 = 750mV - Default 11: V2 = 800mV
  0xA84 CAL_CTL6 reset 0x6CAD7 — Cal control - SA CTL LP/ULP trims
    [19:18] SA_CTL_TRIM_T6_LP_HV — SA_CTL_TRIM_T6_LP_HV<1>= eni (enable current trim) SA_CTL_TRIM_T6_LP_HV<0> = ecn (enable cap trim)
    [17:15] SA_CTL_TRIM_T5_LP_HV — SA_CTL_TRIM_T5_LP_HV<2>= evi (integration current trim) SA_CTL_TRIM_T5_LP_HV<1:0> = evc (integration cap trim)
    [14:12] SA_CTL_TRIM_T4_LP_HV — SA_CTL_TRIM_T4_LP_HV<2>= eqi (eq current trim) SA_CTL_TRIM_T4_LP_HV<1:0> = eqc (eq cap trim)
    [11:10] SA_CTL_TRIM_T1_LP_HV — clk_trk delay
    [9:8] SA_CTL_TRIM_T6_ULP_HV — SA_CTL_TRIM_T6_ULP_HV<1>= eni (enable current trim) SA_CTL_TRIM_T6_ULP_HV<0> = ecn (enable cap trim)
    [7:5] SA_CTL_TRIM_T5_ULP_HV — SA_CTL_TRIM_T5_ULP_HV<2>= evi (integration current trim) SA_CTL_TRIM_T5_ULP_HV<1:0> = evc (integration cap trim)
    [4:2] SA_CTL_TRIM_T4_ULP_HV — SA_CTL_TRIM_T4_ULP_HV<2>= eqi (eq current trim) SA_CTL_TRIM_T4_ULP_HV<1:0> = eqc (eq cap trim)
    [1:0] SA_CTL_TRIM_T1_ULP_HV — clk_trk delay
  0xA88 CAL_CTL7 reset 0x18C00 — Cal control - ERSX8_CLK_SEL, FM_ACTIVE, TURBO_EXT
    [19:17] SPARE3_CTL7_LP_HV
    [16:15] PTRIM_LP_HV — SA PBIAS Trim for LP Operation
    [14:12] SPARE2_CTL7_ULP_HV
    [11:10] PTRIM_ULP_HV — SA PBIAS Trim for ULP Operation
    [9:8] SPARE_CTL7_HV
    [7] READY_DEL_HV — 0: Ready Delay trim. 1: Ready Delay trim.
    [6] ERSX8_EN_ALL_HV — 0': Staggered turn on/off of GWL 1: GWL are turned on/off at the same time (old FM legacy)
    [5] FM_READY_DIS_HV — 0': fm ready is enabled 1: fm ready is disabled (fm_ready is always '1')
    [4] NPDAC_HWCTL_DIS_HV — 0': ndac, pdac staircase hardware controlled 1: ndac, pdac staircase disabled. Enables FW control.
    [3] TURBO_EXT_HV — 0: Normal operation 1: Uses external turbo pulse
    [2] FM_ACTIVE_HV — 0: Normal operation 1: Forces FM SYS in active mode
    [1:0] ERSX8_CLK_SEL_HV — Clock frequency into the ersx8 shift register block 00: Oscillator clock 01: Oscillator clock / 2 10: Oscillator clock / 4 11: Oscillator clock / 8
  {0xB00+4j} FM_PL_ECC[{j}] (j=0..32) — Flash macro Page Latches ECC
    [24:16] DATA9_1 ro — ECC encoder output. Can be read any time at address 0xa00
    [8:0] DATA9 — if_sel must be 1 Normal PL ECC data read: one page latch Byte When reading the page latches it requires FM_CTL.IF_SEL to be '1' Note: the high Voltage page latches are readable for test mode functionality. Only even addresses, address step =8.
  {0xC00+4j} FM_MEM_DATA[{j}] (j=0..131) ro — Flash macro memory sense amplifier data
    [31:0] DATA32 — Sense amplifier and column multiplexer structure Bytes. The read data is dependent on FM_CTL.IF_SEL - IF_SEL is 0: data as specified by the R interface address; If accessed when IF_SEL=0, the data read is not valid. - IF_SEL is 1: data as specified by FM_MEM_ADDR and the offset of the accessed FM_MEM_DATA register. Four FM data out Bytes. Each access is a full FM core read through C-BUS. The row address is given by the FM_ADDRESS register, the word and column addresses are driven by c_addr bus.
  {0xF00+4j} FM_MEM_ECC[{j}] (j=0..32) ro — Flash macro memory sense amplifier ECC.
    [8:0] ECC_PARITY — Sense amplifier ECC Bits. FM_CTL.IF_SEL must be 1. FM ECC data. Each access is a full FM core read through C-BUS. The row address is given by the FM_ADDRESS register, the word and column addresses are driven by c_addr bus.
  0xFEC FM_ECC_CTL_ADDR ro — Internal ECC signal - unused
    [0] ECC_CTL_ADDR — Internal Register - Spare for future use - Read Undefined, Write Ignore
  0xFF0 FM_RED_CTL_SM01_ADDR ro — 0
    [31:0] FM_RED_CTL_SM01_ADDR — Internal Register - Spare for future use - Read Undefined, Write Ignore
  0xFF4 FM_RED_CTL67_ADDR ro — 0
    [31:0] FM_RED_CTL67_ADDR — Internal Register - Spare for future use - Read Undefined, Write Ignore
  0xFF8 FM_RED_CTL45_ADDR ro — 0
    [31:0] FM_RED_CTL45_ADDR — Internal Register - Spare for future use - Read Undefined, Write Ignore
  0xFFC FM_CAL_CTL8_ADDR ro — 0
    [31:0] FM_CAL_CTL8_ADDR — Internal Register - Spare for future use - Read Undefined, Write Ignore
